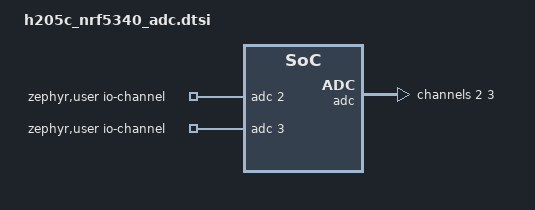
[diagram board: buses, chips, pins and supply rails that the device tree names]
/*
 * Copyright (c) 2022 Acme CPU
 *
 * Created on: 7-Dec-2022
 * Author: Rohan Dey (rohan@acmecpu.cpm)
 *
 * H205C ADC channels
 *      - Channel 2 - Vbat voltage
 *      - Channel 3 - VBUS voltage
 */

/ {
	zephyr,user {
		io-channels = <&adc 2>, <&adc 3>;
	};
};

&adc {
	#address-cells = <1>;
	#size-cells = <0>;

	vbat: channel@2 {
		reg = <2>;
		zephyr,gain = "ADC_GAIN_1_6";
		zephyr,reference = "ADC_REF_INTERNAL";
		zephyr,acquisition-time = <ADC_ACQ_TIME_DEFAULT>;
		zephyr,input-positive = <NRF_SAADC_AIN2>;   /* positive input pin */
		zephyr,resolution = <12>;
	};

	vbus: channel@3 {
		reg = <3>;
		zephyr,gain = "ADC_GAIN_1_6";
		zephyr,reference = "ADC_REF_INTERNAL";
		zephyr,acquisition-time = <ADC_ACQ_TIME_DEFAULT>;
		zephyr,input-positive = <NRF_SAADC_AIN3>;   /* positive input pin */
		zephyr,resolution = <12>;
	};
};
